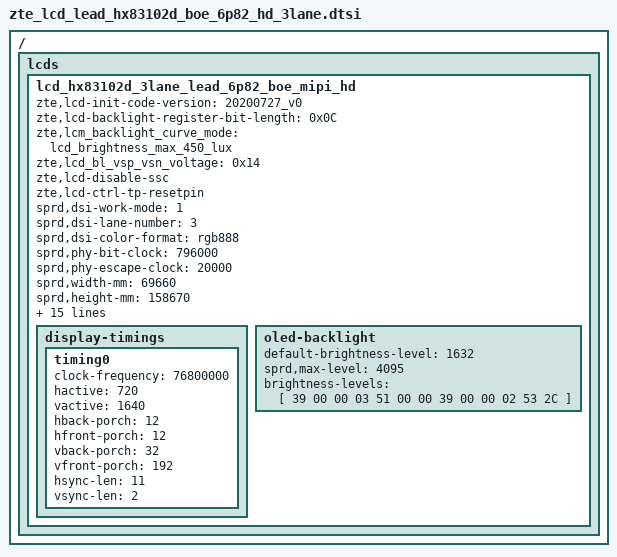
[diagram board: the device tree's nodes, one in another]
/ { lcds {
	lcd_hx83102d_3lane_lead_6p82_boe_mipi_hd: lcd_hx83102d_3lane_lead_6p82_boe_mipi_hd {
		zte,lcd-init-code-version = "20200727_v0";
		zte,lcd-backlight-register-bit-length = <0x0C>;
		zte,lcm_backlight_curve_mode = "lcd_brightness_max_450_lux";
		zte,lcd_bl_vsp_vsn_voltage = <0x14>;
		zte,lcd-disable-ssc;
		zte,lcd-ctrl-tp-resetpin;

		sprd,dsi-work-mode = <1>; /* video burst mode*/
		sprd,dsi-lane-number = <3>;
		sprd,dsi-color-format = "rgb888";

		sprd,phy-bit-clock = <796000>;  /* kbps */
		sprd,phy-escape-clock = <20000>;/* kHz */

		sprd,width-mm = <69660>;
		sprd,height-mm = <158670>;
		zte,panel-name = "lcd_hx83102d_mipi_lead_6p82_boe_himax_hd";
		sprd,esd-check-enable = <1>;/* 0:close , 1:open */
		sprd,esd-check-mode = <1>;/* 0:REG ,1:TE  */
		sprd,esd-check-period = <1000>;
		sprd,esd-check-register = <0x0A>;
		sprd,esd-check-value = <0x9C>;

		sprd,reset-on-sequence = <1 5>, <0 5>, <1 35>;
		sprd,reset-off-sequence = <1 5>,<1 1>, <1 1>;
		sprd,initial-command = [
39 00 00 04 b9 83 10 2d
39 00 00 02 cd 01
39 00 00 0c b1 22 44 31 31 22 37 31 43 08 08 08
39 00 00 0f b2 00 00 06 68 00 08 be 37 13 00 00 01 85 a0
39 00 00 0f b4 02 3d 23 60 03 46 03 46 03 fc 00 00 01 ff
39 00 00 02 cc 02
39 00 00 27 d3 00 00 01 01 00 08 08 37 00 33 39 1c 1c 00 00
	32 10 18 00 18 54 16 8f 06 8f 32 10 14 00 14 00
	00 00 1a 00 00 00 1a
39 00 00 02 bd 01
39 00 00 04 d3 09 00 78
39 00 00 02 bd 00
39 00 00 2d d5 18 18 18 18 18 18 19 19 19 19 39 39 39 39 24
	24 04 05 04 05 06 07 06 07 00 01 00 01 02 03 02
	03 18 18 18 18 38 38 38 38 20 21 22 23
39 00 00 2d d6 18 18 19 19 19 19 18 18 18 18 39 39 39 39 24
	24 03 02 03 02 01 00 01 00 07 06 07 06 05 04 05
	04 18 18 18 18 38 38 38 38 23 22 21 20
39 00 00 03 e7 ff 0f
39 00 00 02 bd 01
39 00 00 02 e7 01
39 00 00 02 bd 00
39 00 00 02 bd 02
39 00 00 0d d8 ff ff ff ff ff f0 ff ff ff ff ff f0
39 00 00 02 bd 00
39 00 00 2f e0 00 02 06 0a 0e 10 24 2b 33 33 52 5f 6c 82 87
	97 a5 bd c0 61 6a 76 7f 00 02 06 0a 0e 10 24 2b
	33 33 52 5f 6c 82 87 97 a5 bd c0 61 6a 76 7f
39 00 00 14 ba 71 23 a8 93 b2 c0 c0 01 10 00 00 00 0d 3d 82
	77 04 01 04
39 00 00 08 bf fc 00 04 9e f6 00 5d
39 00 00 06 cb 00 13 00 02 58
39 00 00 02 bd 01
39 00 00 02 cb 01
39 00 00 02 bd 02
39 00 00 09 b4 42 00 33 00 33 88 b3 33
39 00 00 04 b1 7f 03 f5
39 00 00 02 bd 00
39 00 00 06 c7 00 c2 00 10 42
39 00 00 04 c9 04 08 80
39 00 00 02 35 00
39 00 00 03 51 00 00
39 00 00 02 53 24
39 00 00 02 55 00
39 00 00 03 5E 00 00
05 64 00 01 11
39 00 00 02 bd 01
39 00 00 02 b1 01
39 00 00 02 bd 00
39 00 00 04 b9 00 00 00
05 20 00 01 29
			];
		sprd,sleep-in-command = [
			13 0A 00 01 28
			13 78 00 01 10
			];
		sprd,sleep-out-command = [
			13 78 00 01 11
			13 64 00 01 29
			];

		display-timings {
			timing0 {
			clock-frequency = <76800000>;
			hactive = <720>;
			vactive = <1640>;
			hback-porch = <12>;
			hfront-porch = <12>;
			vback-porch = <32>;
			vfront-porch = <192>;
			hsync-len = <11>;
			vsync-len = <2>;
			};
		};
		oled-backlight {
			default-brightness-level = <1632>;
			sprd,max-level = <4095>;
			brightness-levels = [
				39 00 00 03 51 00 00
				39 00 00 02 53 2C
			];
		};
	};
};};

